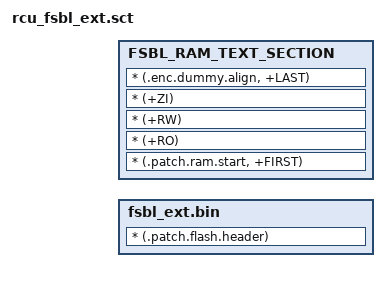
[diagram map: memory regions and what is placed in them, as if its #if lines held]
#! armcc -E
#include "..\inc\fsbl_ext_define.h"
; *************************************************************
; *** Scatter-Loading Description File generated by uVision ***
; *************************************************************

#define FSBL_RAM_TEXT_SECTION_ADDR   FSBL_RAM_ADDR
#define FSBL_RAM_TEXT_SECTION_SIZE   FSBL_RAM_SIZE


; Load region of flash for patch
LOAD_Flash FSBL_FLASH_ADR FSBL_FLASH_SIZE
{
    fsbl_ext.bin FSBL_FLASH_ADR
    {
        * (.patch.flash.header)
    }

    FSBL_RAM_TEXT_SECTION FSBL_RAM_TEXT_SECTION_ADDR FSBL_RAM_TEXT_SECTION_SIZE
    {
        * (.patch.ram.start, +FIRST)
        * (+RO)
        * (+RW)
        * (+ZI)
#if FSBL_RAM_CODE_ENCRYPTED
        * (.enc.dummy.align, +LAST)
#endif
    }

}
